# LM3S9D92 register map
File version: 7944
Registers are 32-bit, read-write, no defined reset value unless marked. A register's access mark holds for its fields unless they carry their own. Offsets are from the block's base; [hi:lo] are bit positions; {n}, {i} and the like mark numbered series; 'fields as' and 'values as' point back to an identical list.

## EPI0 — Register map for EPI0 peripheral
Base 0x400D0000; register names take the prefix EPI0
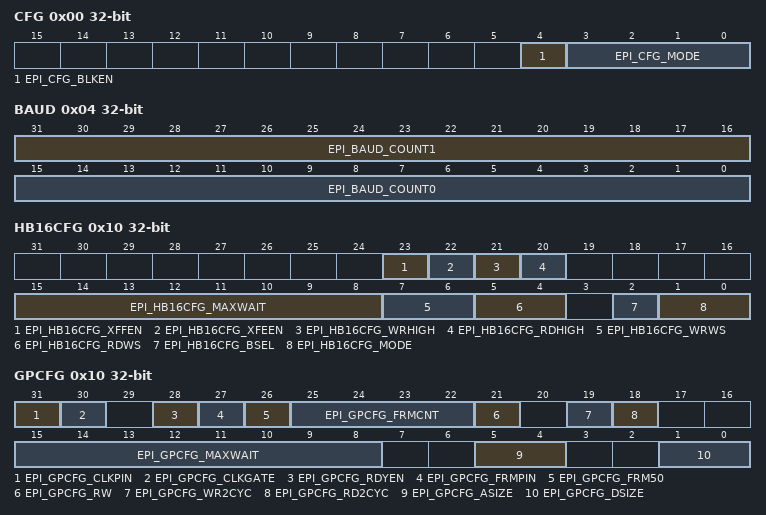
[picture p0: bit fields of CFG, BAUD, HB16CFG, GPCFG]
0x00 CFG — EPI Configuration
  [4] EPI_CFG_BLKEN — Block Enable
  [3:0] EPI_CFG_MODE — Mode Select
    0=EPI_CFG_MODE_NONE (General Purpose); 1=EPI_CFG_MODE_SDRAM (SDRAM); 2=EPI_CFG_MODE_HB8 (8-Bit Host-Bus (HB8)); 3=EPI_CFG_MODE_HB16 (16-Bit Host-Bus (HB16))
0x04 BAUD — EPI Main Baud Rate
  [31:16] EPI_BAUD_COUNT1 — Baud Rate Counter 1
  [15:0] EPI_BAUD_COUNT0 — Baud Rate Counter 0
0x10 HB16CFG (EPI_ALT16 view) — EPI Host-Bus 16 Configuration
  [23] EPI_HB16CFG_XFFEN — External FIFO FULL Enable
  [22] EPI_HB16CFG_XFEEN — External FIFO EMPTY Enable
  [21] EPI_HB16CFG_WRHIGH — WRITE Strobe Polarity
  [20] EPI_HB16CFG_RDHIGH — READ Strobe Polarity
  [15:8] EPI_HB16CFG_MAXWAIT — Maximum Wait
  [7:6] EPI_HB16CFG_WRWS — CS0n Write Wait States
    0=No wait states; 1=1 wait state; 2=2 wait states; 3=3 wait states
  [5:4] EPI_HB16CFG_RDWS — CS0n Read Wait States
    values as EPI_HB16CFG_WRWS
  [2] EPI_HB16CFG_BSEL — Byte Select Configuration
  [1:0] EPI_HB16CFG_MODE — Host Bus Sub-Mode
    0=EPI_HB16CFG_MODE_ADMUX (ADMUX - AD[15:0]); 1=EPI_HB16CFG_MODE_ADNMUX (ADNONMUX - D[15:0]); 2=EPI_HB16CFG_MODE_SRAM (Continuous Read - D[15:0]); 3=EPI_HB16CFG_MODE_XFIFO (XFIFO - D[15:0])
0x10 GPCFG — EPI General-Purpose Configuration
  [31] EPI_GPCFG_CLKPIN — Clock Pin
  [30] EPI_GPCFG_CLKGATE — Clock Gated
  [28] EPI_GPCFG_RDYEN — Ready Enable
  [27] EPI_GPCFG_FRMPIN — Framing Pin
  [26] EPI_GPCFG_FRM50 — 50/50 Frame
  [25:22] EPI_GPCFG_FRMCNT — Frame Count
  [21] EPI_GPCFG_RW — Read and Write
  [19] EPI_GPCFG_WR2CYC — 2-Cycle Writes
  [18] EPI_GPCFG_RD2CYC — 2-Cycle Reads
  [15:8] EPI_GPCFG_MAXWAIT — Maximum Wait
  [5:4] EPI_GPCFG_ASIZE — Address Bus Size
    0=EPI_GPCFG_ASIZE_NONE (No address); 1=EPI_GPCFG_ASIZE_4BIT (Up to 4 bits wide); 2=EPI_GPCFG_ASIZE_12BIT (Up to 12 bits wide. This size cannot be used with 24-bit data); 3=EPI_GPCFG_ASIZE_20BIT (Up to 20 bits wide. This size cannot be used with data sizes other than 8)
  [1:0] EPI_GPCFG_DSIZE — Size of Data Bus
    0=EPI_GPCFG_DSIZE_4BIT (8 Bits Wide (EPI0S0 to EPI0S7)); 1=EPI_GPCFG_DSIZE_16BIT (16 Bits Wide (EPI0S0 to EPI0S15)); 2=EPI_GPCFG_DSIZE_24BIT (24 Bits Wide (EPI0S0 to EPI0S23)); 3=EPI_GPCFG_DSIZE_32BIT (32 Bits Wide (EPI0S0 to EPI0S31))
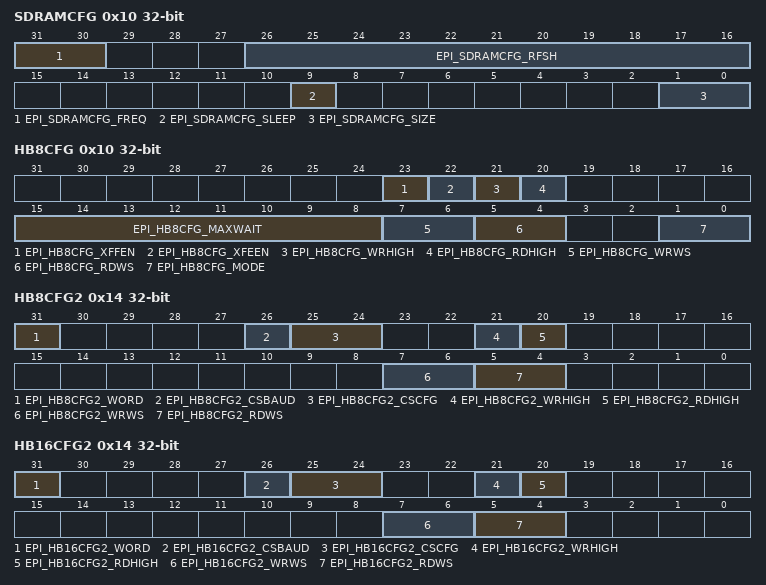
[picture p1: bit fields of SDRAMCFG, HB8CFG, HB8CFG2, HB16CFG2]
0x10 SDRAMCFG (EPI_ALTSD view) — EPI SDRAM Configuration
  [31:30] EPI_SDRAMCFG_FREQ — Frequency Range
    0=EPI_SDRAMCFG_FREQ_NONE (0 - 15 MHz); 1=EPI_SDRAMCFG_FREQ_15MHZ (15 - 30 MHz); 2=EPI_SDRAMCFG_FREQ_30MHZ (30 - 50 MHz); 3=EPI_SDRAMCFG_FREQ_50MHZ (50 - 100 MHz)
  [26:16] EPI_SDRAMCFG_RFSH — Refresh Counter
  [9] EPI_SDRAMCFG_SLEEP — Sleep Mode
  [1:0] EPI_SDRAMCFG_SIZE — Size of SDRAM
    0=EPI_SDRAMCFG_SIZE_8MB (64 megabits (8MB)); 1=EPI_SDRAMCFG_SIZE_16MB (128 megabits (16MB)); 2=EPI_SDRAMCFG_SIZE_32MB (256 megabits (32MB)); 3=EPI_SDRAMCFG_SIZE_64MB (512 megabits (64MB))
0x10 HB8CFG (EPI_ALT8 view) — EPI Host-Bus 8 Configuration
  [23] EPI_HB8CFG_XFFEN — External FIFO FULL Enable
  [22] EPI_HB8CFG_XFEEN — External FIFO EMPTY Enable
  [21] EPI_HB8CFG_WRHIGH — CS0n WRITE Strobe Polarity
  [20] EPI_HB8CFG_RDHIGH — CS0n READ Strobe Polarity
  [15:8] EPI_HB8CFG_MAXWAIT — Maximum Wait
  [7:6] EPI_HB8CFG_WRWS — Write Wait States
    values as HB16CFG.EPI_HB16CFG_WRWS
  [5:4] EPI_HB8CFG_RDWS — Read Wait States
    values as HB16CFG.EPI_HB16CFG_WRWS
  [1:0] EPI_HB8CFG_MODE — Host Bus Sub-Mode
    0=EPI_HB8CFG_MODE_MUX (ADMUX - AD[7:0]); 1=EPI_HB8CFG_MODE_NMUX (ADNONMUX - D[7:0]); 2=EPI_HB8CFG_MODE_SRAM (Continuous Read - D[7:0]); 3=EPI_HB8CFG_MODE_FIFO (XFIFO - D[7:0])
0x14 HB8CFG2 (EPI_ALT8 view) — EPI Host-Bus 8 Configuration 2
  [31] EPI_HB8CFG2_WORD — Word Access Mode
  [26] EPI_HB8CFG2_CSBAUD — Chip Select Baud Rate
  [25:24] EPI_HB8CFG2_CSCFG — Chip Select Configuration
    0=EPI_HB8CFG2_CSCFG_ALE (ALE Configuration); 1=EPI_HB8CFG2_CSCFG_CS (CSn Configuration); 2=EPI_HB8CFG2_CSCFG_DCS (Dual CSn Configuration); 3=EPI_HB8CFG2_CSCFG_ADCS (ALE with Dual CSn Configuration)
  [21] EPI_HB8CFG2_WRHIGH — CS1n WRITE Strobe Polarity
  [20] EPI_HB8CFG2_RDHIGH — CS1n READ Strobe Polarity
  [7:6] EPI_HB8CFG2_WRWS — CS1n Write Wait States
    values as HB16CFG.EPI_HB16CFG_WRWS
  [5:4] EPI_HB8CFG2_RDWS — CS1n Read Wait States
    values as HB16CFG.EPI_HB16CFG_WRWS
0x14 HB16CFG2 (EPI_ALT16 view) — EPI Host-Bus 16 Configuration 2
  [31] EPI_HB16CFG2_WORD — Word Access Mode
  [26] EPI_HB16CFG2_CSBAUD — Chip Select Baud Rate
  [25:24] EPI_HB16CFG2_CSCFG — Chip Select Configuration
    0=EPI_HB16CFG2_CSCFG_ALE (ALE Configuration); 1=EPI_HB16CFG2_CSCFG_CS (CSn Configuration); 2=EPI_HB16CFG2_CSCFG_DCS (Dual CSn Configuration); 3=EPI_HB16CFG2_CSCFG_ADCS (ALE with Dual CSn Configuration)
  [21] EPI_HB16CFG2_WRHIGH — CS1n WRITE Strobe Polarity
  [20] EPI_HB16CFG2_RDHIGH — CS1n READ Strobe Polarity
  [7:6] EPI_HB16CFG2_WRWS — CS1n Write Wait States
    values as HB16CFG.EPI_HB16CFG_WRWS
  [5:4] EPI_HB16CFG2_RDWS — CS1n Read Wait States
    values as HB16CFG.EPI_HB16CFG_WRWS
0x14 GPCFG2 — EPI General-Purpose Configuration 2
  [31] EPI_GPCFG2_WORD — Word Access Mode
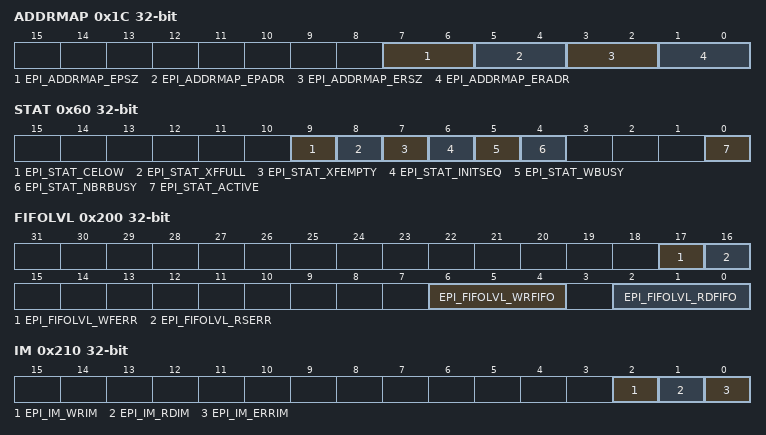
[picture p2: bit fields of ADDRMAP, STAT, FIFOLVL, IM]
0x1C ADDRMAP — EPI Address Map
  [7:6] EPI_ADDRMAP_EPSZ — External Peripheral Size
    0=EPI_ADDRMAP_EPSZ_256B (256 bytes; lower address range: 0x00 to 0xFF); 1=EPI_ADDRMAP_EPSZ_64KB (64 KB; lower address range: 0x0000 to 0xFFFF); 2=EPI_ADDRMAP_EPSZ_16MB (16 MB; lower address range: 0x00.0000 to 0xFF.FFFF); 3=EPI_ADDRMAP_EPSZ_256MB (256 MB; lower address range: 0x000.0000 to 0xFFF.FFFF)
  [5:4] EPI_ADDRMAP_EPADR — External Peripheral Address
    0=EPI_ADDRMAP_EPADR_NONE (Not mapped); 1=EPI_ADDRMAP_EPADR_A000 (At 0xA000.0000); 2=EPI_ADDRMAP_EPADR_C000 (At 0xC000.0000)
  [3:2] EPI_ADDRMAP_ERSZ — External RAM Size
    0=EPI_ADDRMAP_ERSZ_256B (256 bytes; lower address range: 0x00 to 0xFF); 1=EPI_ADDRMAP_ERSZ_64KB (64 KB; lower address range: 0x0000 to 0xFFFF); 2=EPI_ADDRMAP_ERSZ_16MB (16 MB; lower address range: 0x00.0000 to 0xFF.FFFF); 3=EPI_ADDRMAP_ERSZ_256MB (256 MB; lower address range: 0x000.0000 to 0xFFF.FFFF)
  [1:0] EPI_ADDRMAP_ERADR — External RAM Address
    0=EPI_ADDRMAP_ERADR_NONE (Not mapped); 1=At 0x6000.0000; 2=At 0x8000.0000
0x20 RSIZE0 — EPI Read Size 0
  [1:0] EPI_RSIZE0_SIZE — Current Size
    1=EPI_RSIZE0_SIZE_8BIT (Byte (8 bits)); 2=EPI_RSIZE0_SIZE_16BIT (Half-word (16 bits)); 3=EPI_RSIZE0_SIZE_32BIT (Word (32 bits))
0x24 RADDR0 — EPI Read Address 0
  [28:0] EPI_RADDR0_ADDR — Current Address
0x28 RPSTD0 — EPI Non-Blocking Read Data 0
  [12:0] EPI_RPSTD0_POSTCNT — Post Count
0x30 RSIZE1 — EPI Read Size 1
  [1:0] EPI_RSIZE1_SIZE — Current Size
    1=EPI_RSIZE1_SIZE_8BIT (Byte (8 bits)); 2=EPI_RSIZE1_SIZE_16BIT (Half-word (16 bits)); 3=EPI_RSIZE1_SIZE_32BIT (Word (32 bits))
0x34 RADDR1 — EPI Read Address 1
  [28:0] EPI_RADDR1_ADDR — Current Address
0x38 RPSTD1 — EPI Non-Blocking Read Data 1
  [12:0] EPI_RPSTD1_POSTCNT — Post Count
0x60 STAT — EPI Status
  [9] EPI_STAT_CELOW — Clock Enable Low
  [8] EPI_STAT_XFFULL — External FIFO Full
  [7] EPI_STAT_XFEMPTY — External FIFO Empty
  [6] EPI_STAT_INITSEQ — Initialization Sequence
  [5] EPI_STAT_WBUSY — Write Busy
  [4] EPI_STAT_NBRBUSY — Non-Blocking Read Busy
  [0] EPI_STAT_ACTIVE — Register Active
0x6C RFIFOCNT — EPI Read FIFO Count
  [2:0] EPI_RFIFOCNT_COUNT — FIFO Count
0x70 READFIFO — EPI Read FIFO
  [31:0] EPI_READFIFO_DATA — Reads Data
{0x70+4i} READFIFO{i} (i=1..7) — EPI Read FIFO Alias {i}
  [31:0] EPI_READFIFO{i}_DATA — Reads Data
0x200 FIFOLVL — EPI FIFO Level Selects
  [17] EPI_FIFOLVL_WFERR — Write Full Error
  [16] EPI_FIFOLVL_RSERR — Read Stall Error
  [6:4] EPI_FIFOLVL_WRFIFO — Write FIFO
    0=EPI_FIFOLVL_WRFIFO_EMPT (Trigger when there are 1 to 4 spaces available in the WFIFO); 2=EPI_FIFOLVL_WRFIFO_1_4 (Trigger when there are 1 to 3 spaces available in the WFIFO); 3=EPI_FIFOLVL_WRFIFO_1_2 (Trigger when there are 1 to 2 spaces available in the WFIFO); 4=EPI_FIFOLVL_WRFIFO_3_4 (Trigger when there is 1 space available in the WFIFO)
  [2:0] EPI_FIFOLVL_RDFIFO — Read FIFO
    0=EPI_FIFOLVL_RDFIFO_EMPT (Empty); 1=EPI_FIFOLVL_RDFIFO_1_8 (Trigger when there are 1 or more entries in the NBRFIFO); 2=EPI_FIFOLVL_RDFIFO_1_4 (Trigger when there are 2 or more entries in the NBRFIFO); 3=EPI_FIFOLVL_RDFIFO_1_2 (Trigger when there are 4 or more entries in the NBRFIFO); 4=EPI_FIFOLVL_RDFIFO_3_4 (Trigger when there are 6 or more entries in the NBRFIFO); 5=EPI_FIFOLVL_RDFIFO_7_8 (Trigger when there are 7 or more entries in the NBRFIFO); 6=EPI_FIFOLVL_RDFIFO_FULL (Trigger when there are 8 entries in the NBRFIFO)
0x204 WFIFOCNT — EPI Write FIFO Count
  [2:0] EPI_WFIFOCNT_WTAV — Available Write Transactions
0x210 IM — EPI Interrupt Mask
  [2] EPI_IM_WRIM — Write Interrupt Mask
  [1] EPI_IM_RDIM — Read Interrupt Mask
  [0] EPI_IM_ERRIM — Error Interrupt Mask
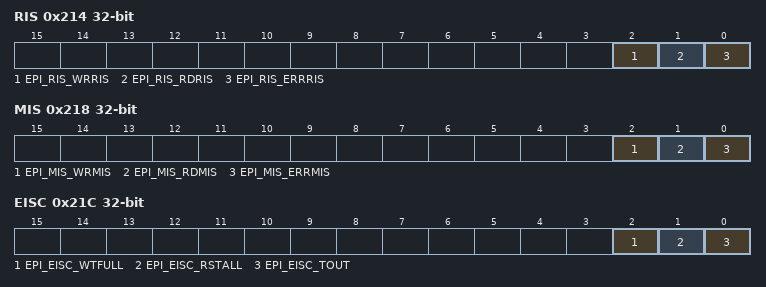
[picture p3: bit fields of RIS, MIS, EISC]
0x214 RIS — EPI Raw Interrupt Status
  [2] EPI_RIS_WRRIS — Write Raw Interrupt Status
  [1] EPI_RIS_RDRIS — Read Raw Interrupt Status
  [0] EPI_RIS_ERRRIS — Error Raw Interrupt Status
0x218 MIS — EPI Masked Interrupt Status
  [2] EPI_MIS_WRMIS — Write Masked Interrupt Status
  [1] EPI_MIS_RDMIS — Read Masked Interrupt Status
  [0] EPI_MIS_ERRMIS — Error Masked Interrupt Status
0x21C EISC — EPI Error Interrupt Status and Clear
  [2] EPI_EISC_WTFULL — Write FIFO Full Error
  [1] EPI_EISC_RSTALL — Read Stalled Error
  [0] EPI_EISC_TOUT — Timeout Error
